VERSION ""

NS_ :

BS_:

BU_: domain sysnode tester

BO_ 288 VehSpeedFrame: 8 domain
 SG_ VehicleSpeed : 0|32@1+ (1,0) [0|4294967295] "km/h" sysnode

BO_ 291 HeadlightCmdFrame: 8 domain
 SG_ HeadlightCmd : 0|32@1+ (1,0) [0|3] "" sysnode

BO_ 294 LedLevelFrame: 8 domain
 SG_ LedLevel : 0|32@1+ (1,0) [0|1000] "permille" sysnode

BO_ 295 HostLedFrame: 8 tester
 SG_ HostLedLevel : 0|32@1+ (1,0) [0|1000] "permille" domain

BO_ 293 SteeringFrame_C: 8 sysnode
 SG_ SteeringAngle : 0|32@1+ (1,0) [0|360] "deg" domain

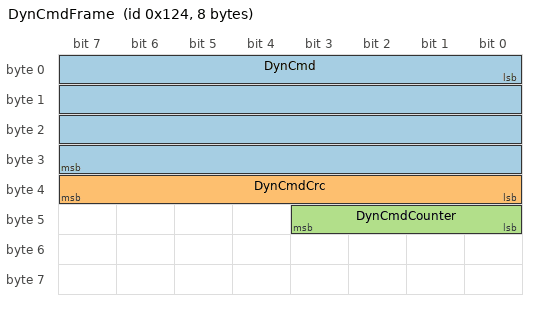
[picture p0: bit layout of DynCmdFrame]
BO_ 292 DynCmdFrame: 8 tester
 SG_ DynCmd : 0|32@1+ (1,0) [0|4294967295] "" domain
 SG_ DynCmdCrc : 32|8@1+ (1,0) [0|255] "" domain
 SG_ DynCmdCounter : 40|4@1+ (1,0) [0|15] "" domain

BO_ 297 DynEchoFrame: 4 domain
 SG_ DynEcho : 0|32@1+ (1,0) [0|4294967295] "" tester

BO_ 298 DynPtFrame: 4 domain
 SG_ DynPt : 0|32@1+ (1,0) [0|4294967295] "" tester

BO_ 299 DynLedFrame: 8 domain
 SG_ DynLed : 0|32@1+ (1,0) [0|1000] "permille" tester

BO_ 300 DynKeptFrame: 4 domain
 SG_ DynKeptOut : 0|32@1+ (1,0) [0|16777215] "" tester

BO_ 320 LoadOutAFrame: 4 domain
 SG_ LoadOutA : 0|32@1+ (1,0) [0|4294967295] "" tester

BO_ 321 LoadOutBFrame: 4 domain
 SG_ LoadOutB : 0|32@1+ (1,0) [0|4294967295] "" tester

BO_ 322 LoadOutCFrame: 4 domain
 SG_ LoadOutC : 0|32@1+ (1,0) [0|4294967295] "" tester

BO_ 323 LoadOutDFrame: 4 domain
 SG_ LoadOutD : 0|32@1+ (1,0) [0|4294967295] "" tester

BO_ 324 LoadOutEFrame: 4 domain
 SG_ LoadOutE : 0|32@1+ (1,0) [0|4294967295] "" tester

BA_DEF_ BO_ "GenMsgCycleTime" INT 0 100000;
BA_DEF_ BO_ "E2ECounterSignal" STRING;
BA_DEF_ BO_ "E2ECrcSignal" STRING;
BA_DEF_ BO_ "E2EProfile" STRING;
BA_DEF_ BO_ "E2EDataId" INT 0 65535;
BA_DEF_ BO_ "E2ETimeout" INT 0 65535;
BA_DEF_DEF_ "GenMsgCycleTime" 0;
BA_ "GenMsgCycleTime" BO_ 288 100;
BA_ "GenMsgCycleTime" BO_ 291 100;
BA_ "GenMsgCycleTime" BO_ 294 100;
BA_ "GenMsgCycleTime" BO_ 295 100;
BA_ "GenMsgCycleTime" BO_ 293 50;
BA_ "GenMsgCycleTime" BO_ 297 100;
BA_ "GenMsgCycleTime" BO_ 298 100;
BA_ "GenMsgCycleTime" BO_ 299 100;
BA_ "GenMsgCycleTime" BO_ 300 100;
BA_ "GenMsgCycleTime" BO_ 320 100;
BA_ "GenMsgCycleTime" BO_ 321 100;
BA_ "GenMsgCycleTime" BO_ 322 100;
BA_ "GenMsgCycleTime" BO_ 323 100;
BA_ "GenMsgCycleTime" BO_ 324 100;
BA_ "E2ECounterSignal" BO_ 292 "DynCmdCounter";
BA_ "E2ECrcSignal" BO_ 292 "DynCmdCrc";
BA_ "E2EProfile" BO_ 292 "P01";
BA_ "E2EDataId" BO_ 292 86;
BA_ "E2ETimeout" BO_ 292 300;
